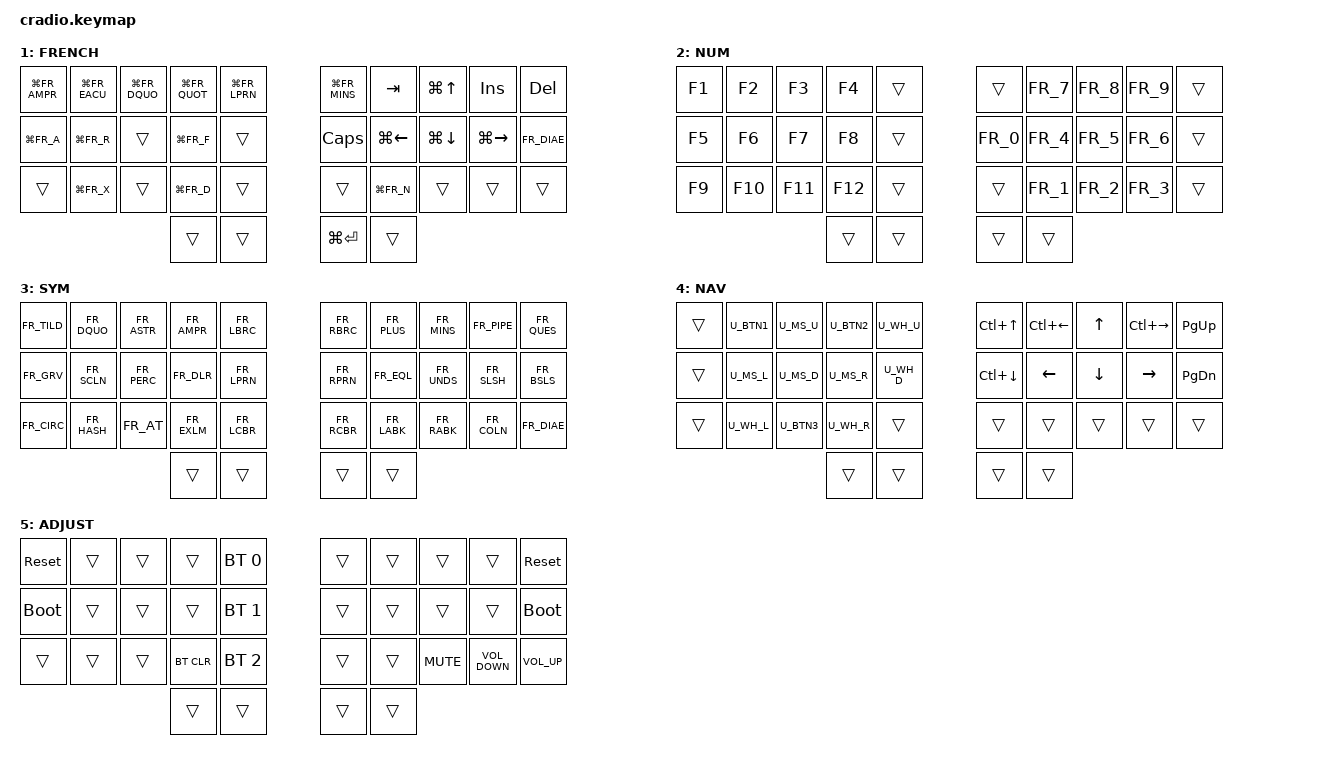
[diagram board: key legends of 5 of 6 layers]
// Copyright (c) 2022 The ZMK Contributors
// SPDX-License-Identifier: MIT

#include <behaviors.dtsi>
#include <dt-bindings/zmk/keys.h>
#include <dt-bindings/zmk/bt.h>
#include "keymap_french.h"
#include "mousekeyspr.h"

// Top row mods macro
#define TRML(k1,k2,k3,k4) &ht LGUI k1  &ht LALT k2  &ht LCTRL k3  &ht LSHFT k4
#define TRMR(k1,k2,k3,k4) &ht RSHFT k1  &ht RCTRL k2  &ht RALT k3  &ht RGUI k4

#define DEFAULT   0
#define FRENCH    1
#define NUM       2
#define SYM       3
#define NAV       4
#define ADJUST    5

#define QUICK_TAP_MS 175 // tapping twice quickly and holding on the second tap sends key repeat

// Define explicit momentary toggle instead of using defaults: https://zmk.dev/docs/behaviors/layers#layer-tap
&lt {
    flavor = "hold-preferred";
    tapping_term_ms = <200>;
    quick-tap-ms = <QUICK_TAP_MS>;
};

/ {
    behaviors {
        ht: hold_tap {
            label = "hold_tap";
            compatible = "zmk,behavior-hold-tap";
            #binding-cells = <2>;
            flavor = "tap-preferred";
            tapping-term-ms = <200>;
            quick-tap-ms = <150>;
            global-quick-tap;
            bindings = <&kp>, <&kp>;
        };
        macro_rst_vim_all_save: macro_rst_vim_all_save {
            compatible = "zmk,behavior-macro";
            label = "RST_VIM_ALL_SAVE";
            #binding-cells = <0>;
            wait-ms = <10>;
            tap-ms = <10>;
            bindings =  <&macro_tap &kp FR_COLN>,
                        <&macro_tap &kp FR_W &kp FR_A &kp FR_L &kp FR_L>,
                        <&macro_tap &kp ENTER>;
        };
    };

    conditional_layers {
        compatible = "zmk,conditional-layers";
        tri_layer {
            if-layers = <1 3>;
            then-layer = <5>;
        };
    };



    combos {
        compatible = "zmk,combos";
        combo_ne_eaigu {
            timeout-ms = <50>;
            key-positions = <16 17>;
            bindings = <&kp FR_EACU>;
        };
        combo_hcomma_egrave {
            timeout-ms = <50>;
            key-positions = <26 27>;
            bindings = <&kp FR_EGRV>;
        };
        combo_xc_ugrave {
            timeout-ms = <50>;
            key-positions = <21 22>;
            bindings = <&kp FR_UGRV>;
        };
        combo_st_agrave {
            timeout-ms = <50>;
            key-positions = <12 13>;
            bindings = <&kp FR_AGRV>;
        };
        combo_cd_ccedille {
            timeout-ms = <50>;
            key-positions = <22 23>;
            bindings = <&kp FR_CCED>;
        };
        combo_rst_vim_all_save {
            timeout-ms = <50>;
            key-positions = <11 12 13>;
            bindings =  <&macro_rst_vim_all_save>;
        };
    };

    keymap {
        compatible = "zmk,keymap";
        default_layer {
            label= "DEFAULT";
            bindings = <
        //╭──────────┬──────────┬──────────┬──────────┬──────────╮   ╭──────────┬──────────┬──────────┬──────────┬──────────╮
        //│  Q       │  W       │  F       │  P       │  B       │   │  J       │  L       │  U       │  Y       │  '       │
           TRML(FR_Q,  FR_W,      FR_F,      FR_P)      &kp FR_B       &kp FR_J  TRMR(FR_L,  FR_U,      FR_Y,      FR_QUOT)
        //├──────────┼──────────┼──────────┼──────────┼──────────┤   ├──────────┼──────────┼──────────┼──────────┼──────────┤
        //│  A       │  R       │  S       │  T       │  G       │   │  M       │  N       │  E       │  I       │ O        │
            &kp FR_A   &kp FR_R   &kp FR_S   &kp FR_T   &kp FR_G       &kp FR_M   &kp FR_N   &kp FR_E   &kp FR_I   &kp FR_O
        //├──────────┼──────────┼──────────┼──────────┼──────────┤   ├──────────┼──────────┼──────────┼──────────┼──────────┤
        //│  Z       │  X       │  C       │  D       │  V       │   │  K       │  H       │  ,       │  .       │  ^       │
            &kp FR_Z   &kp FR_X   &kp FR_C   &kp FR_D  &ht FRENCH FR_V   &kp FR_K   &kp FR_H   &kp FR_COMM  &kp FR_DOT  &kp FR_CIRC
        //╰──────────┴──────────┴──────────┼──────────┼──────────┤   ├──────────┼──────────┼──────────┴──────────┴──────────╯
                                            &lt SYM ESC  &lt NAV SPACE     &lt NUM BSPC   &lt FRENCH ENTER
        //                                 ╰──────────┴──────────╯   ╰──────────┴──────────╯
            >;
        };

        french_layer {
            label= "FRENCH";
            bindings = <
        //╭──────────┬──────────┬──────────┬──────────┬──────────╮   ╭──────────┬──────────┬──────────┬──────────┬──────────╮
        //│ INSERT   │  1       │  2       │  3       │          │   │ HOME     │ PAGE DN  │ PAGE UP  │ END      │  :       │
        &kp LG(FR_AMPR) &kp LG(FR_EACU) &kp LG(FR_DQUO) &kp LG(FR_QUOT) &kp LG(FR_LPRN) &kp LG(FR_MINS) &kp TAB   &kp LG(UP)  &kp INSERT   &kp DEL
        //├──────────┼──────────┼──────────┼──────────┼──────────┤   ├──────────┼──────────┼──────────┼──────────┼──────────┤
        //│ DELETE   │  4       │  5       │  6       │          │   │ LEFT     │ DOWN     │ UP       │ RIGHT    │  ;       │
        &kp LG(FR_A) &kp LG(FR_R)  &trans    &kp LG(FR_F) &trans      &kp CAPS   &kp LG(LEFT) &kp LG(DOWN) &kp LG(RIGHT) &kp FR_DIAE
        //├──────────┼──────────┼──────────┼──────────┼──────────┤   ├──────────┼──────────┼──────────┼──────────┼──────────┤
        //│ CAPS     │  7       │  8       │  9       │  0       │   │          │          │          │          │          │
            &trans   &kp LG(FR_X)  &trans    &kp LG(FR_D) &trans       &trans   &kp LG(FR_N)  &trans     &trans     &trans
        //╰──────────┴──────────┴──────────┼──────────┼──────────┤   ├──────────┼──────────┼──────────┴──────────┴──────────╯
                                             &trans     &trans        &kp LG(ENTER) &trans
        //                                 ╰──────────┴──────────╯   ╰──────────┴──────────╯
            >;
        };

        num_layer {
            label= "NUM";
            bindings = <
        //╭──────────┬──────────┬──────────┬──────────┬──────────╮   ╭──────────┬──────────┬──────────┬──────────┬──────────╮
        //│          │  [       │  {       │  }       │          │   │  ^       │  (       │  )       │  ]       │  ~       │
            &kp F1     &kp F2     &kp F3     &kp F4     &trans         &trans     &kp FR_7   &kp FR_8   &kp FR_9    &trans
        //├──────────┼──────────┼──────────┼──────────┼──────────┤   ├──────────┼──────────┼──────────┼──────────┼──────────┤
        //│  !       │  @       │  #       │  $       │  %       │   │  *       │  -       │  =       │  \       │  `       │
            &kp F5     &kp F6     &kp F7     &kp F8     &trans         &kp FR_0   &kp FR_4   &kp FR_5   &kp FR_6    &trans
        //├──────────┼──────────┼──────────┼──────────┼──────────┤   ├──────────┼──────────┼──────────┼──────────┼──────────┤
        //│          │          │          │          │          │   │  &       │  _       │  +       │  │       │          │
            &kp F9     &kp F10    &kp F11    &kp F12    &trans         &trans     &kp FR_1   &kp FR_2   &kp FR_3    &trans
        //╰──────────┴──────────┴──────────┼──────────┼──────────┤   ├──────────┼──────────┼──────────┴──────────┴──────────╯
                                             &trans     &trans         &trans     &trans
        //                                 ╰──────────┴──────────╯   ╰──────────┴──────────╯
            >;
        };

        sym_layer {
            label= "SYM";
            bindings = <
        //╭──────────┬──────────┬──────────┬──────────┬──────────╮   ╭──────────┬──────────┬──────────┬──────────┬──────────╮
        //│ RESET    │          │          │          │PROFILE 0 │   │          │          │          │          │  RESET   │
          &kp FR_TILD  &kp FR_DQUO  &kp FR_ASTR  &kp FR_AMPR  &kp FR_LBRC   &kp FR_RBRC  &kp FR_PLUS   &kp FR_MINS   &kp FR_PIPE    &kp FR_QUES
        //├──────────┼──────────┼──────────┼──────────┼──────────┤   ├──────────┼──────────┼──────────┼──────────┼──────────┤
        //│BOOTLOADER│          │          │          │PROFILE 1 │   │          │          │          │          │BOOTLOADER│
          &kp FR_GRV  &kp FR_SCLN   &kp FR_PERC   &kp FR_DLR   &kp FR_LPRN   &kp FR_RPRN   &kp FR_EQL   &kp FR_UNDS   &kp FR_SLSH  &kp FR_BSLS
        //├──────────┼──────────┼──────────┼──────────┼──────────┤   ├──────────┼──────────┼──────────┼──────────┼──────────┤
        //│          │          │          │ CLEAR BT │PROFILE 2 │   │          │          │          │          │          │
            &kp FR_CIRC   &kp FR_HASH   &kp FR_AT    &kp FR_EXLM  &kp FR_LCBR  &kp FR_RCBR   &kp FR_LABK   &kp FR_RABK   &kp FR_COLN   &kp FR_DIAE
        //╰──────────┴──────────┴──────────┼──────────┼──────────┤   ├──────────┼──────────┼──────────┴──────────┴──────────╯
                                             &trans     &trans         &trans     &trans
        //                                 ╰──────────┴──────────╯   ╰──────────┴──────────╯
            >;
        };

        nav_layer {
            label= "NAV";
            bindings = <
        //╭──────────┬──────────┬──────────┬──────────┬──────────╮   ╭──────────┬──────────┬──────────┬──────────┬──────────╮
        //│ RESET    │          │          │          │          │   │          │          │          │          │  RESET   │
           &trans      U_BTN1     U_MS_U     U_BTN2     U_WH_U        &kp LC(UP)   &kp LC(LEFT)  &kp UP  &kp LC(RIGHT)  &kp PG_UP
        //├──────────┼──────────┼──────────┼──────────┼──────────┤   ├──────────┼──────────┼──────────┼──────────┼──────────┤
        //│BOOTLOADER│          │          │          │          │   │          │          │          │          │BOOTLOADER│
           &trans      U_MS_L     U_MS_D     U_MS_R     U_WH_D        &kp LC(DOWN)  &kp LEFT  &kp DOWN   &kp RIGHT  &kp PG_DN
        //├──────────┼──────────┼──────────┼──────────┼──────────┤   ├──────────┼──────────┼──────────┼──────────┼──────────┤
        //│          │          │          │          │          │   │          │          │          │          │          │
            &trans     U_WH_L     U_BTN3     U_WH_R     &trans        &trans     &trans     &trans     &trans     &trans
        //╰──────────┴──────────┴──────────┼──────────┼──────────┤   ├──────────┼──────────┼──────────┴──────────┴──────────╯
                                             &trans     &trans         &trans     &trans
        //                                 ╰──────────┴──────────╯   ╰──────────┴──────────╯
            >;
        };

        adjust_layer {
            label= "ADJUST";
            bindings = <
        //╭──────────┬──────────┬──────────┬──────────┬──────────╮   ╭──────────┬──────────┬──────────┬──────────┬──────────╮
        //│ RESET    │          │          │          │PROFILE 0 │   │          │          │          │          │  RESET   │
           &sys_reset  &trans     &trans     &trans    &bt BT_SEL 0    &trans     &trans     &trans     &trans    &sys_reset
        //├──────────┼──────────┼──────────┼──────────┼──────────┤   ├──────────┼──────────┼──────────┼──────────┼──────────┤
        //│BOOTLOADER│          │          │          │PROFILE 1 │   │          │          │          │          │BOOTLOADER│
          &bootloader  &trans     &trans     &trans    &bt BT_SEL 1    &trans     &trans     &trans     &trans    &bootloader
        //├──────────┼──────────┼──────────┼──────────┼──────────┤   ├──────────┼──────────┼──────────┼──────────┼──────────┤
        //│          │          │          │ CLEAR BT │PROFILE 2 │   │          │          │          │          │          │
            &trans     &trans     &trans    &bt BT_CLR &bt BT_SEL 2    &trans     &trans     &kp C_MUTE  &kp C_VOLUME_DOWN   &kp C_VOL_UP
        //╰──────────┴──────────┴──────────┼──────────┼──────────┤   ├──────────┼──────────┼──────────┴──────────┴──────────╯
                                             &trans     &trans         &trans     &trans
        //                                 ╰──────────┴──────────╯   ╰──────────┴──────────╯
            >;
        };
    };
};
